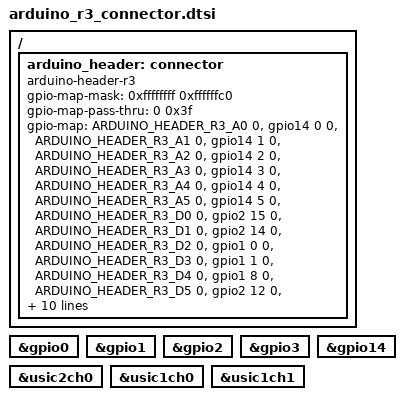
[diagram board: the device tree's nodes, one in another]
/* Copyright (c) 2023 Andriy Gelman
 *
 * SPDX-License-Identifier: Apache-2.0
 */

#include <zephyr/dt-bindings/gpio/arduino-header-r3.h>

/ {
	arduino_header: connector {
		compatible = "arduino-header-r3";
		#gpio-cells = <2>;
		gpio-map-mask = <0xffffffff 0xffffffc0>;
		gpio-map-pass-thru = <0 0x3f>;
		gpio-map = <ARDUINO_HEADER_R3_A0 0 &gpio14 0 0>,
			   <ARDUINO_HEADER_R3_A1 0 &gpio14 1 0>,
			   <ARDUINO_HEADER_R3_A2 0 &gpio14 2 0>,
			   <ARDUINO_HEADER_R3_A3 0 &gpio14 3 0>,
			   <ARDUINO_HEADER_R3_A4 0 &gpio14 4 0>,
			   <ARDUINO_HEADER_R3_A5 0 &gpio14 5 0>,
			   <ARDUINO_HEADER_R3_D0 0 &gpio2 15 0>,
			   <ARDUINO_HEADER_R3_D1 0 &gpio2 14 0>,
			   <ARDUINO_HEADER_R3_D2 0 &gpio1 0 0>,
			   <ARDUINO_HEADER_R3_D3 0 &gpio1 1 0>,
			   <ARDUINO_HEADER_R3_D4 0 &gpio1 8 0>,
			   <ARDUINO_HEADER_R3_D5 0 &gpio2 12 0>,
			   <ARDUINO_HEADER_R3_D6 0 &gpio2 11 0>,
			   <ARDUINO_HEADER_R3_D7 0 &gpio1 9 0>,
			   <ARDUINO_HEADER_R3_D8 0 &gpio1 10 0>,
			   <ARDUINO_HEADER_R3_D9 0 &gpio1 11 0>,
			   <ARDUINO_HEADER_R3_D10 0 &gpio3 10 0>,
			   <ARDUINO_HEADER_R3_D11 0 &gpio3 8 0>,
			   <ARDUINO_HEADER_R3_D12 0 &gpio3 7 0>,
			   <ARDUINO_HEADER_R3_D13 0 &gpio3 9 0>,
			   <ARDUINO_HEADER_R3_D14 0 &gpio3 15 0>,
			   <ARDUINO_HEADER_R3_D15 0 &gpio0 13 0>;
	};
};

&gpio0 {
	status = "okay";
};

&gpio1 {
	status = "okay";
};

&gpio2 {
	status = "okay";
};

&gpio3 {
	status = "okay";
};

&gpio14 {
	status = "okay";
};

arduino_spi: &usic2ch0 {};
arduino_serial: &usic1ch0 {};
arduino_i2c: &usic1ch1 {};
